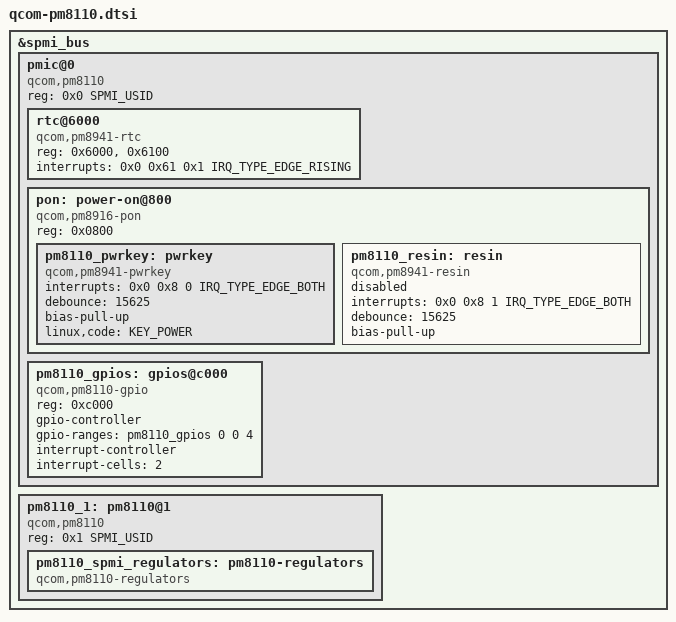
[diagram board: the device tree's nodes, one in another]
// SPDX-License-Identifier: BSD-3-Clause
/*
 * Copyright (c) 2021, Ivaylo Ivanov <ivo.ivanov@null.net>
 */

#include <dt-bindings/input/linux-event-codes.h>
#include <dt-bindings/interrupt-controller/irq.h>
#include <dt-bindings/input/input.h>
#include <dt-bindings/spmi/spmi.h>

&spmi_bus {

	pmic@0 {
		compatible = "qcom,pm8110", "qcom,spmi-pmic";
		reg = <0x0 SPMI_USID>;
		#address-cells = <1>;
		#size-cells = <0>;

		rtc@6000 {
			compatible = "qcom,pm8941-rtc";
			reg = <0x6000>, <0x6100>;
			reg-names = "rtc", "alarm";
			interrupts = <0x0 0x61 0x1 IRQ_TYPE_EDGE_RISING>;
		};

		pon: power-on@800 {
			compatible = "qcom,pm8916-pon";
			reg = <0x0800>;

			pm8110_pwrkey: pwrkey {
				compatible = "qcom,pm8941-pwrkey";
				interrupts = <0x0 0x8 0 IRQ_TYPE_EDGE_BOTH>;
				debounce = <15625>;
				bias-pull-up;
				linux,code = <KEY_POWER>;
			};

			pm8110_resin: resin {
				compatible = "qcom,pm8941-resin";
				interrupts = <0x0 0x8 1 IRQ_TYPE_EDGE_BOTH>;
				debounce = <15625>;
				bias-pull-up;

				status = "disabled";
			};
		};

		pm8110_gpios: gpios@c000 {
			compatible = "qcom,pm8110-gpio";
			reg = <0xc000>;
			gpio-controller;
			gpio-ranges = <&pm8110_gpios 0 0 4>;
			#gpio-cells = <2>;
			interrupt-controller;
			interrupt-cells =<2>;
		};
	};

	pm8110_1: pm8110@1 {
		compatible = "qcom,pm8110", "qcom,spmi-pmic";
		reg = <0x1 SPMI_USID>;
		#address-cells = <1>;
		#size-cells = <0>;

		pm8110_spmi_regulators: pm8110-regulators {
			compatible = "qcom,pm8110-regulators";
		};
	};
};
